# tviibh16m register map
Vendor: Infineon Technologies; Series: TVIIBH16M; File version: 1.0
CPU: CM7 r0p1, little endian, MPU, FPU, double-precision FPU, I-cache, D-cache, VTOR, ITCM, DTCM, 3 interrupt priority bits, 16 interrupts
Registers are 32-bit, read-write, reset 0x0 unless marked. A register's access mark holds for its fields unless they carry their own. Offsets are from the block's base; [hi:lo] are bit positions; {n}, {i} and the like mark numbered series; 'fields as' and 'values as' point back to an identical list.

## ETH0 (part 3 of 3) — Ethernet Interface
Base 0x40480000
Same registers: ETH1 0x40490000
0x11F8 TSU_PEER_RX_SEC ro — PTP Peer Event Frame Received Seconds Register (31 to 0 bits)
  [31:0] TIMER_PEER_SEC — PTP Peer Event Frame Received Seconds. The register is updated with the value that the 1588 timer seconds register held when the SFD of a PTP receive peer event crosses the MII interface. The actual update occurs when the GEM recognizes the frame as a PTP pdelay_req or pdelay_resp frame. An interrupt is issued when the register is updated.
0x11FC TSU_PEER_RX_NSEC ro — PTP Peer Event Frame Received Nanoseconds Register
  [29:0] TIMER_PEER_NSEC — PTP Peer Event Frame Received Nanoseconds. The register is updated with the value that the 1588 timer nanoseconds register held when the SFD of a PTP receive peer event crosses the MII interface. The actual update occurs when the GEM recognizes the frame as a PTP pdelay_req or pdelay_resp frame. An interrupt is issued when the register is updated.
0x1200 PCS_CONTROL ro — Not presents. Access to the register returns AHB error.
  [31:0] REMOVED_31_0 — Write ignore, read 0
0x1204 PCS_STATUS ro — Not presents. Access to the register returns AHB error.
  [31:0] REMOVED_31_0 — Write ignore, read 0
0x1210 PCS_AN_ADV ro — Not presents. Access to the register returns AHB error.
  [31:0] REMOVED_31_0 — Write ignore, read 0
0x1214 PCS_AN_LP_BASE ro — Not presents. Access to the register returns AHB error.
  [31:0] REMOVED_31_0 — Write ignore, read 0
0x1218 PCS_AN_EXP ro — Not presents. Access to the register returns AHB error.
  [31:0] REMOVED_31_0 — Write ignore, read 0
0x121C PCS_AN_NP_TX ro — Not presents. Access to the register returns AHB error.
  [31:0] REMOVED_31_0 — Write ignore, read 0
0x1220 PCS_AN_LP_NP ro — Not presents. Access to the register returns AHB error.
  [31:0] REMOVED_31_0 — Write ignore, read 0
0x123C PCS_AN_EXT_STATUS ro — Not presents. Access to the register returns AHB error.
  [31:0] REMOVED_31_0 — Write ignore, read 0
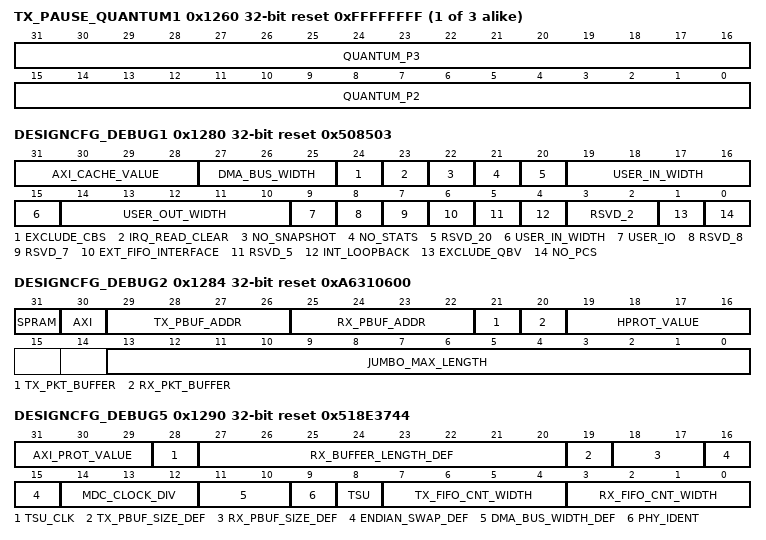
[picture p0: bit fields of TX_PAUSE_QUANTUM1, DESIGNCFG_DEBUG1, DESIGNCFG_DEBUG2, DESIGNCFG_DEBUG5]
{0x125C+4i} TX_PAUSE_QUANTUM{i} reset 0xFFFFFFFF (i=1..3) — Transmit Pause Quantum Register {i}
  [31:16] QUANTUM_P{2i+1} — Transmit pause quantum - written with the pause quantum value for pause frame transmission of priority {2i+1}.
  [15:0] QUANTUM_P{2i} — Transmit pause quantum - written with the pause quantum value for pause frame transmission of priority {2i}.
0x1270 RX_LPI ro — Received LPI transitions
  [15:0] COUNT_LPI read-clears — Count of RX LPI transitions. A count of the number of times there is a transition from receiving normal idle to receiving low power idle. Cleared on read.
0x1274 RX_LPI_TIME ro — Received LPI time
  [23:0] LPI_TIME read-clears — Time in LPI. This register increments once every 16 pclk cycles when the LPI indication bit 20 is set in the receive configuration register. Cleared on read.
0x1278 TX_LPI ro — Transmit LPI transitions
  [15:0] COUNT_LPI read-clears — Count of LPI transmissions. A count of the number of times the enable LPI transmission bit 20 goes from low to high in the transmit control register.
0x127C TX_LPI_TIME ro — Transmit LPI time
  [23:0] LPI_TIME read-clears — Time in LPI. This register increments once every 16 pclk cycles when the enable LPI transmission bit 20 is set in the transmit control register. Cleared on read.
0x1280 DESIGNCFG_DEBUG1 ro reset 0x508503 — The GEM_GXL(3PIP) has many parameterisation options to configure the IP during compilation stage. This is achieved using Verilog define compiler directives in an include file called mxeth_defs.v.
  [31:28] AXI_CACHE_VALUE — Takes the value of the `gem_axi_cache_value DEFINE
  [27:25] DMA_BUS_WIDTH — Takes the value of bits 7:5 of the `gem_dma_bus_width DEFINE. So if the define is set to decimal 64 this will return binary 010.
  [24] EXCLUDE_CBS — Takes the value of the `gem_exclude_cbs DEFINE
  [23] IRQ_READ_CLEAR — Takes the value of the `gem_irq_read_clear DEFINE
  [22] NO_SNAPSHOT — Takes the value of the `gem_no_snapshot DEFINE
  [21] NO_STATS — Takes the value of the `gem_no_stats DEFINE
  [20] RSVD_20
  [19:15] USER_IN_WIDTH — Takes the value of the `gem_user_in_width DEFINE `gem_user_io. If 'gem_user_io is not set, the value is 0x01
  [14:10] USER_OUT_WIDTH — Takes the value of the `gem_user_out_width DEFINE if `gem_user_io is set. If 'gem_user_io is not set, the value is 0x01
  [9] USER_IO — Takes the value of the `gem_user_io DEFINE
  [8] RSVD_8
  [7] RSVD_7
  [6] EXT_FIFO_INTERFACE — Takes the value of the `gem_ext_fifo_interface DEFINE
  [5] RSVD_5
  [4] INT_LOOPBACK — Takes the value of the `gem_int_loopback DEFINE
  [3:2] RSVD_2
  [1] EXCLUDE_QBV — Takes the value of the `gem_exclude_qbv DEFINE
  [0] NO_PCS — Takes the value of the `gem_no_pcs DEFINE
0x1284 DESIGNCFG_DEBUG2 ro reset 0xA6310600 — Design Configuration Register 2
  [31] SPRAM — Takes the value of the `gem_spram DEFINE
  [30] AXI — Takes the value of the `gem_axi DEFINE
  [29:26] TX_PBUF_ADDR — Takes the value of the `gem_tx_pbuf_addr DEFINE
  [25:22] RX_PBUF_ADDR — Takes the value of the `gem_rx_pbuf_addr DEFINE
  [21] TX_PKT_BUFFER — Takes the value of the `gem_tx_pkt_buffer DEFINE
  [20] RX_PKT_BUFFER — Takes the value of the `gem_rx_pkt_buffer DEFINE
  [19:16] HPROT_VALUE — Takes the value of the `gem_hprot_value DEFINE
  [13:0] JUMBO_MAX_LENGTH — Takes the value of the `gem_jumbo_max_length DEFINE
0x1288 DESIGNCFG_DEBUG3 ro reset 0x4000000 — Design Configuration Register 3
  [29:24] NUM_SPEC_ADD_FILTERS — Takes the value of the `num_spec_add_filters DEFINE
0x128C DESIGNCFG_DEBUG4 ro — Design Configuration Register 4
  [31:0] RSVD_31_0
0x1290 DESIGNCFG_DEBUG5 ro reset 0x518E3744 — Design Configuration Register 5
  [31:29] AXI_PROT_VALUE — Takes the value of the `gem_axi_prot_value DEFINE
  [28] TSU_CLK — Takes the value of the `gem_tsu_clk DEFINE
  [27:20] RX_BUFFER_LENGTH_DEF — Takes the value of the `gem_rx_buffer_length_def DEFINE
  [19] TX_PBUF_SIZE_DEF — Takes the value of the `gem_tx_pbuf_size_def DEFINE
  [18:17] RX_PBUF_SIZE_DEF — Takes the value of the `gem_rx_pbuf_size_def DEFINE
  [16:15] ENDIAN_SWAP_DEF — Takes the value of the `gem_endian_swap_def DEFINE
  [14:12] MDC_CLOCK_DIV — Takes the value of the `gem_mdc_clock_div DEFINE
  [11:10] DMA_BUS_WIDTH_DEF — Takes the value of the `gem_dma_bus_width_def DEFINE
  [9] PHY_IDENT — Takes the value of the `gem_phy_ident DEFINE
  [8] TSU — Takes the value of the `gem_tsu DEFINE
  [7:4] TX_FIFO_CNT_WIDTH — Takes the value of the `gem_tx_fifo_cnt_width DEFINE
  [3:0] RX_FIFO_CNT_WIDTH — Takes the value of the `gem_rx_fifo_cnt_width DEFINE
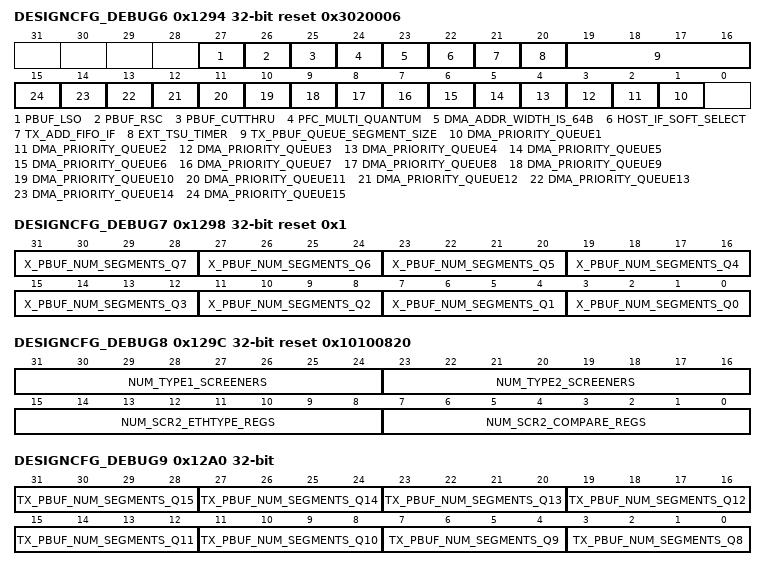
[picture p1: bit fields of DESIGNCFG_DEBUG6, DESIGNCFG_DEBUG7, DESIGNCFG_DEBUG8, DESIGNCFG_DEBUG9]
0x1294 DESIGNCFG_DEBUG6 ro reset 0x3020006 — Design Configuration Register 6
  [27] PBUF_LSO — Takes the value of the `gem_pbuf_lso DEFINE
  [26] PBUF_RSC — Takes the value of the `gem_pbuf_rsc DEFINE
  [25] PBUF_CUTTHRU — Takes the value of the `gem_pbuf_cutthru DEFINE
  [24] PFC_MULTI_QUANTUM — Takes the value of the `gem_pfc_multi_quantum DEFINE
  [23] DMA_ADDR_WIDTH_IS_64B — Takes the value of the `gem_dma_addr_width_is_64b DEFINE
  [22] HOST_IF_SOFT_SELECT — Takes the value of the `gem_host_if_soft_select DEFINE
  [21] TX_ADD_FIFO_IF — Takes the value of the `gem_tx_add_fifo_if DEFINE
  [20] EXT_TSU_TIMER — Takes the value of the `gem_ext_tsu_timer DEFINE
  [19:16] TX_PBUF_QUEUE_SEGMENT_SIZE — Takes the value of the `gem_tx_pbuf_queue_segment_size DEFINE
  [n] DMA_PRIORITY_QUEUE{n} (n=1..15) — Takes the value of the `dma_priority_queue{n} DEFINE
0x1298 DESIGNCFG_DEBUG7 ro reset 0x1 — Design Configuration Register 7
  [4n+3:4n] X_PBUF_NUM_SEGMENTS_Q{n} (n=0..7) — Takes the value of the `gem_tx_pbuf_num_segments_q{n} DEFINE
0x129C DESIGNCFG_DEBUG8 ro reset 0x10100820 — Design Configuration Register 8
  [31:24] NUM_TYPE1_SCREENERS — Takes the value of the `num_type1_screeners DEFINE
  [23:16] NUM_TYPE2_SCREENERS — Takes the value of the `num_type2_screeners DEFINE
  [15:8] NUM_SCR2_ETHTYPE_REGS — Takes the value of the `num_scr2_ethtype_regs DEFINE
  [7:0] NUM_SCR2_COMPARE_REGS — Takes the value of the `num_scr2_compare_regs DEFINE
0x12A0 DESIGNCFG_DEBUG9 ro — Design Configuration Register 9
  [4n-29:4n-32] TX_PBUF_NUM_SEGMENTS_Q{n} (n=8..15) — Takes the value of the `gem_tx_pbuf_num_segments_q{n} DEFINE
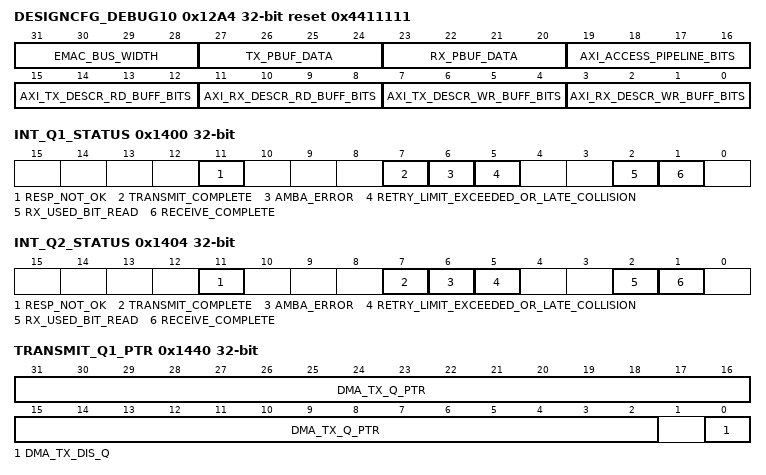
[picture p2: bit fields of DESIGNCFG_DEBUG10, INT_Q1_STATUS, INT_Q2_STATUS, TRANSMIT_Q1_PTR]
0x12A4 DESIGNCFG_DEBUG10 ro reset 0x4411111 — Design Configuration Register 10
  [31:28] EMAC_BUS_WIDTH — Takes the value of the `gem_emac_bus_width DEFINE. 1 - The MAC has a datawidth of 32bits. 2 - The MAC has a datawidth of 64bits. 4 - The MAC has a datawidth of 128bits
  [27:24] TX_PBUF_DATA — Takes the value of the `gem_tx_pbuf_data DEFINE. 1 - The TX DPRAM has a datawidth of 32bits. 2 - The TX DPRAM has a datawidth of 64bits. 4 - The TX DPRAM has a datawidth of 128bits
  [23:20] RX_PBUF_DATA — Takes the value of the `gem_rx_pbuf_data DEFINE. 1 - The RX DPRAM has a datawidth of 32bits. 2 - The RX DPRAM has a datawidth of 64bits. 4 - RX The DPRAM has a datawidth of 128bits
  [19:16] AXI_ACCESS_PIPELINE_BITS — Takes the value of the `gem_axi_access_pipeline_bits DEFINE
  [15:12] AXI_TX_DESCR_RD_BUFF_BITS — Takes the value of the `gem_axi_tx_descr_rd_buff_bits DEFINE
  [11:8] AXI_RX_DESCR_RD_BUFF_BITS — Takes the value of the `gem_axi_rx_descr_rd_buff_bits DEFINE
  [7:4] AXI_TX_DESCR_WR_BUFF_BITS — Takes the value of the `gem_axi_tx_descr_wr_buff_bits DEFINE
  [3:0] AXI_RX_DESCR_WR_BUFF_BITS — Takes the value of the `gem_axi_rx_descr_wr_buff_bits DEFINE
0x1300 SPEC_ADD5_BOTTOM ro — Specific address registers 5 ~ 36 doesn't present. Access to the register returns AHB error.
  [31:0] RSVD_31_0 — Write ignore, read 0
0x1304 SPEC_ADD5_TOP ro — Specific address registers 5 ~ 36 doesn't present. Access to the register returns AHB error.
  [31:0] RSVD_31_0 — Write ignore, read 0
0x13F8 SPEC_ADD36_BOTTOM ro — Not presents.
  [31:0] RSVD_31_0 — Write ignore, read 0
0x13FC SPEC_ADD36_TOP ro — Not presents.
  [31:0] RSVD_31_0 — Write ignore, read 0
0x1400 INT_Q1_STATUS ro — Priority queue Interrupt Status Register
  [11] RESP_NOT_OK — bresp not OK
  [7] TRANSMIT_COMPLETE
  [6] AMBA_ERROR — Transmit frame corruption due to AMBA (AXI/AHB) error set if an error occurs whilst midway through reading transmit frame from the external memory, including HRESP (AHB), RRESP and BRESP errors (AXI) and buffers exhausted mid frame
  [5] RETRY_LIMIT_EXCEEDED_OR_LATE_COLLISION
  [2] RX_USED_BIT_READ
  [1] RECEIVE_COMPLETE
0x1404 INT_Q2_STATUS ro — Priority queue Interrupt Status Register
  [11] RESP_NOT_OK — bresp not OK
  [7] TRANSMIT_COMPLETE
  [6] AMBA_ERROR — Transmit frame corruption due to AMBA (AXI/AHB) error set if an error occurs whilst midway through reading transmit frame from the external memory, including HRESP(AHB), RRESP and BRESP errors (AXI) and buffers exhausted mid frame
  [5] RETRY_LIMIT_EXCEEDED_OR_LATE_COLLISION
  [2] RX_USED_BIT_READ
  [1] RECEIVE_COMPLETE
0x1408 INT_Q3_STATUS ro — int_q3_status to int_q15_status doesn't present. Access to the register returns AHB error.
  [31:0] REMOVED_31_0 — Write ignore, read 0
0x1438 INT_Q15_STATUS ro — Not presents.
  [31:0] REMOVED_31_0 — Write ignore, read 0
0x1440 TRANSMIT_Q1_PTR — This register holds the start address of the transmit buffer queue (transmit buffers descriptor list). The transmit buffer queue base address register must be initialized before transmit is started through bit 9 of the network control register. Once transmission has started, any write to the transmit buffer queue base address register is illegal and therefore ignored. Note that due to clock boundary synchronization, it takes a maximum of four pclk cycles from the writing of the transmit start bit before the transmitter is active. Writing to the transmit buffer queue base address register during this time may produce unpredictable results. Reading this register returns the location of the descriptor currently being accessed. Because the DMA can store data for multiple frames at once, this may not necessarily be pointing to the current frame being transmitted. In terms of AMBA AXI operation, the transmit descriptors are written to memory using a single 32bit AHB access. When the datapath is configured as 64bit , the transmit descriptors should be aligned at 64-bit boundaries and each pair of 32-bit descriptors is read from memory using a single AXI access.
  [31:2] DMA_TX_Q_PTR — This register holds the start address of the transmit buffer queue (transmit buffers descriptor list). The transmit buffer queue base address register must be initialized before transmit is started through bit 9 of the network control register. Once transmission has started, any write to the transmit buffer queue base address register is illegal and therefore ignored. Note that due to clock boundary synchronization, it takes a maximum of four pclk cycles from the writing of the transmit start bit before the transmitter is active. Writing to the transmit buffer queue base address register during this time may produce unpredictable results. Reading this register returns the location of the descriptor currently being accessed. Because the DMA can store data for multiple frames at once, this may not necessarily be pointing to the current frame being transmitted. In terms of AMBA AHB/AXI operation, the transmit descriptors are written to memory using a single 32bit AHB access. When the datapath is configured as 64bit or 128bit, the transmit descriptors should be aligned at 64-bit boundaries and each pair of 32-bit descriptors is read from memory using a single AHB/AXI access. For 32bit datapaths, the descriptors should be aligned at 32-bit boundaries and the descriptors are read from memory using two individual 32-bit non sequential accesses.
  [0] DMA_TX_DIS_Q — Disable queue if set to 1. This can be used to reduce the number of active queues and should only be changed while transmit is not enabled.
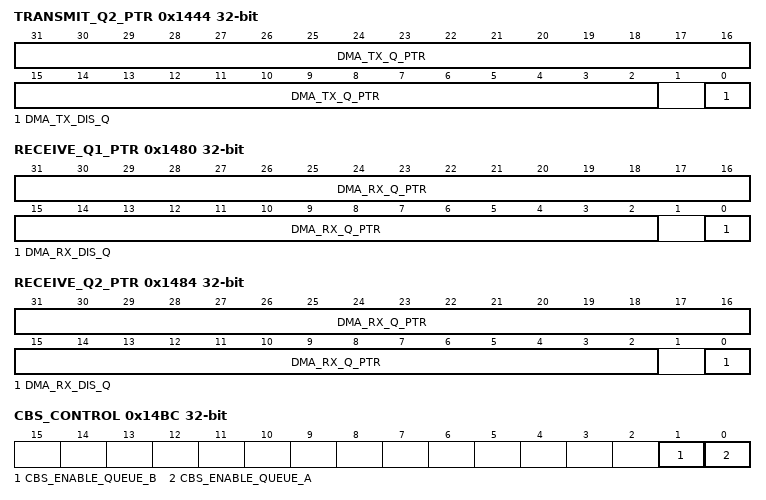
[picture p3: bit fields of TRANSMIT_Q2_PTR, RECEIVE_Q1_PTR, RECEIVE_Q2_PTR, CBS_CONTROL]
0x1444 TRANSMIT_Q2_PTR — This register holds the start address of the transmit buffer queue (transmit buffers descriptor list). The transmit buffer queue base address register must be initialized before transmit is started through bit 9 of the network control register. Once transmission has started, any write to the transmit buffer queue base address register is illegal and therefore ignored. Note that due to clock boundary synchronization, it takes a maximum of four pclk cycles from the writing of the transmit start bit before the transmitter is active. Writing to the transmit buffer queue base address register during this time may produce unpredictable results. Reading this register returns the location of the descriptor currently being accessed. Because the DMA can store data for multiple frames at once, this may not necessarily be pointing to the current frame being transmitted. In terms of AMBA AXI operation, the transmit descriptors are written to memory using a single 32bit AHB access. When the datapath is configured as 64bit , the transmit descriptors should be aligned at 64-bit boundaries and each pair of 32-bit descriptors is read from memory using a single AXI access.
  [31:2] DMA_TX_Q_PTR — This register holds the start address of the transmit buffer queue (transmit buffers descriptor list). The transmit buffer queue base address register must be initialized before transmit is started through bit 9 of the network control register. Once transmission has started, any write to the transmit buffer queue base address register is illegal and therefore ignored. Note that due to clock boundary synchronization, it takes a maximum of four pclk cycles from the writing of the transmit start bit before the transmitter is active. Writing to the transmit buffer queue base address register during this time may produce unpredictable results. Reading this register returns the location of the descriptor currently being accessed. Because the DMA can store data for multiple frames at once, this may not necessarily be pointing to the current frame being transmitted. In terms of AMBA AHB/AXI operation, the transmit descriptors are written to memory using a single 32bit AHB access. When the datapath is configured as 64bit or 128bit, the transmit descriptors should be aligned at 64-bit boundaries and each pair of 32-bit descriptors is read from memory using a single AHB/AXI access. For 32bit datapaths, the descriptors should be aligned at 32-bit boundaries and the descriptors are read from memory using two individual 32-bit non sequential accesses
  [0] DMA_TX_DIS_Q — Disable queue if set to 1. This can be used to reduce the number of active queues and should only be changed while transmit is not enabled.
0x1448 TRANSMIT_Q3_PTR ro — transmit_q3_ptr to transmit_q15_ptr doesn't present. Access to the register returns AHB error.
  [31:0] REMOVED_31_0 — Disable queue if set to 1. This can be used to reduce the number of active queues and should only be changed while transmit is not enabled.
0x1478 TRANSMIT_Q15_PTR ro — Not presents.
  [31:0] REMOVED_31_0 — Write ignore, read 0
0x1480 RECEIVE_Q1_PTR — This register holds the start address of the transmit buffer queue (transmit buffers descriptor list). The transmit buffer queue base address register must be initialized before transmit is started through bit 9 of the network control register. Once transmission has started, any write to the transmit buffer queue base address register is illegal and therefore ignored. Note that due to clock boundary synchronization, it takes a maximum of four pclk cycles from the writing of the transmit start bit before the transmitter is active. Writing to the transmit buffer queue base address register during this time may produce unpredictable results. Reading this register returns the location of the descriptor currently being accessed. Because the DMA can store data for multiple frames at once, this may not necessarily be pointing to the current frame being transmitted. In terms of AMBA AXI operation, the transmit descriptors are written to memory using a single 32bit AHB access. When the datapath is configured as 64bit , the transmit descriptors should be aligned at 64-bit boundaries and each pair of 32-bit descriptors is read from memory using a single AXI access.
  [31:2] DMA_RX_Q_PTR — Receive buffer queue base address - written with the address of the start of the receive queue.
  [0] DMA_RX_DIS_Q — Disable queue if set to 1. This can be used to reduce the number of active queues and should only be changed while receive is not enabled.
0x1484 RECEIVE_Q2_PTR — This register holds the start address of the transmit buffer queue (transmit buffers descriptor list). The transmit buffer queue base address register must be initialized before transmit is started through bit 9 of the network control register. Once transmission has started, any write to the transmit buffer queue base address register is illegal and therefore ignored. Note that due to clock boundary synchronization, it takes a maximum of four pclk cycles from the writing of the transmit start bit before the transmitter is active. Writing to the transmit buffer queue base address register during this time may produce unpredictable results. Reading this register returns the location of the descriptor currently being accessed. Because the DMA can store data for multiple frames at once, this may not necessarily be pointing to the current frame being transmitted. In terms of AMBA AXI operation, the transmit descriptors are written to memory using a single 32bit AHB access. When the datapath is configured as 64bit , the transmit descriptors should be aligned at 64-bit boundaries and each pair of 32-bit descriptors is read from memory using a single AXI access.
  fields as RECEIVE_Q1_PTR
0x1488 RECEIVE_Q3_PTR ro — Not presents. Start address register doesn't present for queue3 ~ queue7.
  [31:0] REMOVED_31_0 — Write ignore, read 0
0x1498 RECEIVE_Q7_PTR ro — Not presents.
  [31:0] REMOVED_31_0 — Write ignore, read 0
0x14A0 DMA_RXBUF_SIZE_Q1 reset 0x18 — Receive Buffer queue 1 Size
  [7:0] DMA_RX_Q_BUF_SIZE — DMA receive buffer size in system memory. The value defined by these bits determines the size of buffer to use in main system memory when writing received data. The value is defined in multiples of 64 bytes. 0x01 corresponds to buffers of 64 bytes. 0x02 corresponds to 128 bytes etc. For example: 0x02: 128 byte 0x18: 1536 byte (1*max length frame/buffer) 0xA0: 10240 byte (1*10K jumbo frame/buffer) Note that this value should never be written as zero. Note. The reset value of this field is equal to the gem_rx_buffer_length_def define, which is user configurable.
0x14A4 DMA_RXBUF_SIZE_Q2 reset 0x18 — Receive Buffer queue 2 Size
  fields as DMA_RXBUF_SIZE_Q1
0x14A8 DMA_RXBUF_SIZE_Q3 ro — dma_rxbuf_size_q3 to dma_rxbuf_size_q7 doesn't present.
  [31:0] REMOVED_31_0 — DMA receive buffer size in system memory. The value defined by these bits determines the size of buffer to use in main system memory when writing received data. The value is defined in multiples of 64 bytes. 0x01 corresponds to buffers of 64 bytes. 0x02 corresponds to 128 bytes etc. For example: 0x02: 128 byte 0x18: 1536 byte (1*max length frame/buffer) 0xA0: 10240 byte (1*10K jumbo frame/buffer) Note that this value should never be written as zero. Note. The reset value of this field is equal to the gem_rx_buffer_length_def define, which is user configurable.
0x14B8 DMA_RXBUF_SIZE_Q7 ro — Not presents.
  [31:0] REMOVED_31_0 — Write ignore, read 0
0x14BC CBS_CONTROL — The IdleSlope value is defined as the rate of change of credit when a packet is waiting to be sent. This must not exceed the portTransmitRate which is dependent on the speed of operation, eg, portTranmsitRate. 1Gb/s = 32'h07735940 (125 Mbytes/s), 100Mb/sec = 32'h017D7840 (25 Mnibbles/s), 10Mb/sec = 32'h002625A0 (2.5 Mnibbles/s). If 50 percent of bandwidth was to be allocated to a particular queue in 1Gb/sec mode then the IdleSlope value for that queue would be calculated as 32'h07735940/2. Note that Credit-Based Shaping should be disabled prior to updating the IdleSlope values. As another example, for a 1722 audio packet with a payload of 6 samples per channel, the packet size would be 7 (preamble) + 1 (SFD) + 50 (packet header) + 6x4x2(payload) + 4 (CRC) = 110 bytes. For a rate of 8000 packets per second, the desired rate would 110 x 8000 bytes per second, so the programmed idleSlope value would be 880000 for a 1Gb/s connection, or 1760000 for a 100Mb/s or 10Mbs connection. See Figure 6.3 in the IEEE 1722 standard. In practice, the actual transmission rate will be vary slightly from that calculated. In this case, the idleSlope value should be recalibrated based on the variance between the measured and expected rate, and in this case very accurate transmission rates can be achieved.
  [1] CBS_ENABLE_QUEUE_B — Enable Credit-Based shaping on the 2nd highest priority queue (queue B). Write 1 to enable
  [0] CBS_ENABLE_QUEUE_A — Enable Credit-Based Shaping on the highest priority queue (queue A). Write 1 to enable
0x14C0 CBS_IDLESLOPE_Q_A — queue A is the highest priority queue. This would be queue 8 in an 8 queue configuration.
  [31:0] IDLESLOPE_A — IdleSlope value for queue A in bytes/sec for gigabit operation and nibbles/sec for 10/100 operation
0x14C4 CBS_IDLESLOPE_Q_B — queue B is the 2nd highest priority queue. This would be queue 7 in an 8 queue configuration.
  [31:0] IDLESLOPE_B — IdleSlope value for queue B in bytes/sec for gigabit operation and nibbles/sec for 10/100 operation
0x14C8 UPPER_TX_Q_BASE_ADDR — Upper 32 bits of transmit buffer descriptor queue base address.
  [31:0] UPPER_TX_Q_BASE_ADDR — Upper 32 bits of transmit buffer descriptor queue base address. Used when 64 bit addressing is enabled. (In releases earlier to 1p06f2 this register also affected the receive descriptor queue.)
0x14CC TX_BD_CONTROL
  [5:4] TX_BD_TS_MODE — TX Descriptor Timestamp Insertion mode, 00: TS insertion disable, 01: TS inserted for PTP Event Frames only, 10: TS inserted for All PTP Frames only, 11: TS insertion for All Frames
0x14D0 RX_BD_CONTROL
  [5:4] RX_BD_TS_MODE — RX Descriptor Timestamp Insertion mode, 00: TS insertion disable, 01: TS inserted for PTP Event Frames only, 10: TS inserted for All PTP Frames only, 11: TS insertion for All Frames
0x14D4 UPPER_RX_Q_BASE_ADDR — Upper 32 bits of receive buffer descriptor queue base address.
  [31:0] UPPER_RX_Q_BASE_ADDR — Upper 32 bits of receive buffer descriptor queue base address. Used when 64 bit addressing is enabled.
0x14E0 HIDDEN_REG0 reset 0x2625A0 — Hidden registers defined in edma_defs.v '`define gem_cbs_port_tx_rate_10m 12'h4e0 // 10M Port TX Rate *** HIDDEN Register ***'. Default value of cbs related hidden registers (0x14E0~0x14E8) are depicted in cbs_control register.
  [31:0] HIDDEN0_FIELD — default value is defined per description of register cbs_control.
0x14E4 HIDDEN_REG1 reset 0x17D7840 — Hidden registers defined in edma_defs.v '`define gem_cbs_port_tx_rate_100m 12'h4e4 // 100M Port TX Rate *** HIDDEN Register ***'
  [31:0] HIDDEN1_FIELD — default value is defined per description of register cbs_control.
0x14E8 HIDDEN_REG2 reset 0x7735940 — Hidden registers defined in edma_defs.v '`define gem_cbs_port_tx_rate_1g 12'h4e8 // 1G Port TX Rate *** HIDDEN Register ***'
  [31:0] HIDDEN2_FIELD — default value is defined per description of register cbs_control.
0x14EC HIDDEN_REG3 reset 0x7 — Hidden registers defined in edma_defs.v '`define gem_wd_counter 12'h4ec // *** HIDDEN Register ***'.
  [3:0] HIDDEN3_FIELD — default value is defined per description of register cbs_control.
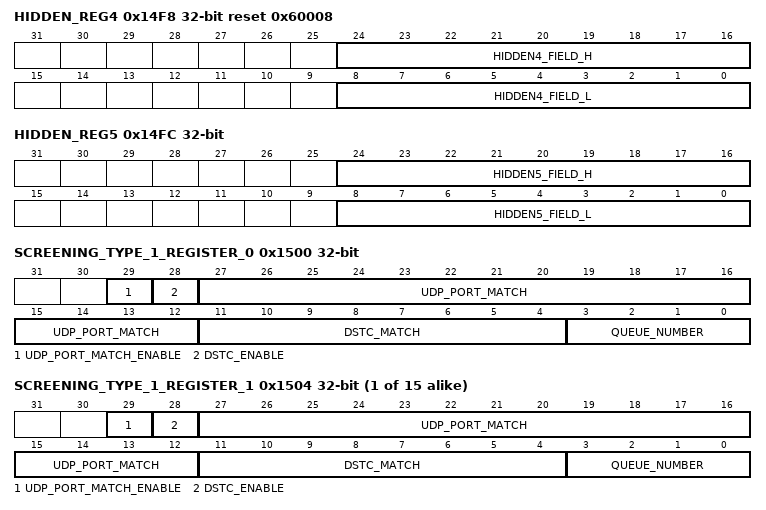
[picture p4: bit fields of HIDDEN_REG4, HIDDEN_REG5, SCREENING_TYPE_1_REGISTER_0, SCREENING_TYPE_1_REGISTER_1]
0x14F8 HIDDEN_REG4 reset 0x60008 — Hidden registers defined in edma_defs.v '`define gem_axi_tx_full_threshold0 12'h4f8 // AXI full threshold setting *** HIDDEN Register ***'. Note. When using AXI mode with a single port ram ( gem_spram == 1) mode and a 32b dma bus width ( gem_dma_bus_width == 32 or bits 22 to 21 of the network_config register are set to 0) the AXI hidden registers (0x14F8 and 0x14FC) need to be updated (these registers are used for fine tuning AXI dma bursts and normally should not be touched).
  [24:16] HIDDEN4_FIELD_H — The valid bits is defined by `gem_tx_pbuf_addr.
  [8:0] HIDDEN4_FIELD_L — The valid bits is defined by `gem_tx_pbuf_addr.
0x14FC HIDDEN_REG5 — Hidden registers defined in edma_defs.v '`define gem_axi_tx_full_threshold1 12'h4fc // AXI full threshold setting *** HIDDEN Register ***'.
  [24:16] HIDDEN5_FIELD_H — The valid bits is defined by `gem_tx_pbuf_addr.
  [8:0] HIDDEN5_FIELD_L — The valid bits is defined by `gem_tx_pbuf_addr.
0x1500 SCREENING_TYPE_1_REGISTER_0 — Screening type 1 registers are used to allocate up to 16 priority queues to received frames based on certain IP or UDP fields of incoming frames. Firstly, when DS/TC match enable is set (bit 28), the DS (Differentiated Services) field of the received IPv4 header or TCfield (traffic class) of IPv6 headers are matched against bits 11 to 4. Secondly, when UDP port match enable is set (bit 29), the UDP Destination Port of the received UDP frame is matched against bits 27 to 12. Both UDP and DS/TC matching can be enabled simultaneously or individually. If a match is successful, then the queue value programmed in bits 2 to 0 is allocated to the frame. The required number of Type 1 screening registers is configured in the gem defines file. Up to 16 type 1 screening registers have been allocated APB address space between 0x500 and 0x53C.
  [29] UDP_PORT_MATCH_ENABLE
  [28] DSTC_ENABLE
  [27:12] UDP_PORT_MATCH
  [11:4] DSTC_MATCH
  [3:0] QUEUE_NUMBER — Queue Number (0 to 15)
{0x1500+4i} SCREENING_TYPE_1_REGISTER_{i} (i=1..15) — screening type 1 register {i}, same as screening_type_1_register_0
  fields as SCREENING_TYPE_1_REGISTER_0
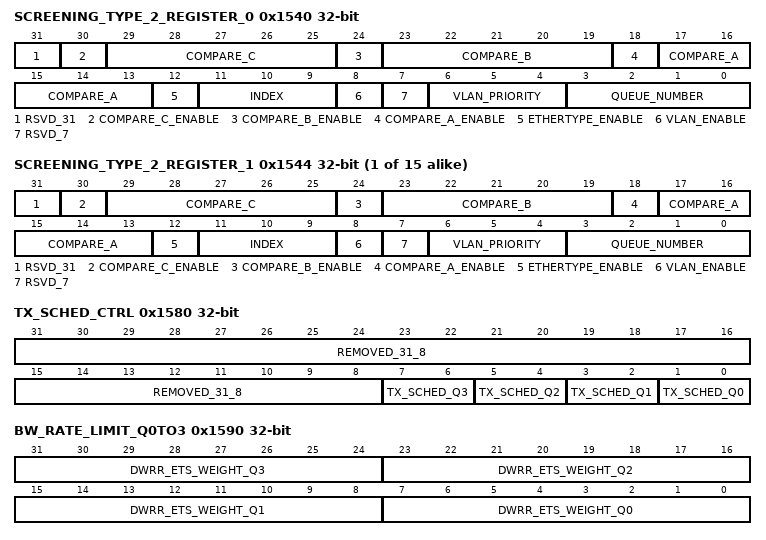
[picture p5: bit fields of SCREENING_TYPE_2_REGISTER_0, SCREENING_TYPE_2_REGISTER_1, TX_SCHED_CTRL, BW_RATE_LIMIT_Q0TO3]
0x1540 SCREENING_TYPE_2_REGISTER_0 — Screener Type 2 match registers operate independently of screener type 1 registers and offer additional match capabilities, extending the capabilities into vendor specific protocols.
  [31] RSVD_31 ro
  [30] COMPARE_C_ENABLE
  [29:25] COMPARE_C — 'Compare C - Index to screener type 2 Compare register'
  [24] COMPARE_B_ENABLE
  [23:19] COMPARE_B — 'Compare B - Index to screener type 2 Compare register'
  [18] COMPARE_A_ENABLE
  [17:13] COMPARE_A — 'Compare A - Index to screener type 2 Compare register '
  [12] ETHERTYPE_ENABLE
  [11:9] INDEX — 'Index to screener type 2 EtherType register'
  [8] VLAN_ENABLE
  [7] RSVD_7
  [6:4] VLAN_PRIORITY
  [3:0] QUEUE_NUMBER — 'Queue Number (0 to 15)'
{0x1540+4i} SCREENING_TYPE_2_REGISTER_{i} (i=1..15) — screening type 2 register {i}, same as screening_type_2_register_0
  fields as SCREENING_TYPE_2_REGISTER_0
0x1580 TX_SCHED_CTRL — This register controls the transmit scheduling algorithm the user can select for each active transmit queue. By default all queues are initialized to fixed priority, with the top indexed queue having overall priority
  [31:8] REMOVED_31_8 ro — Write ignore, read 0
  [7:6] TX_SCHED_Q3 ro — Write ignore, read 0
  [5:4] TX_SCHED_Q2 — 'Queue 2 selection. 00 : Fixed Priority 01 : CBS Enabled only valid for top two enabled queues and if CBS capability selected. 10 : DWRR Enabled 11 : ETS Enabled
  [3:2] TX_SCHED_Q1 — 'Queue 1 selection. 00 : Fixed Priority 01 : CBS Enabled only valid for top two enabled queues and if CBS capability selected. 10 : DWRR Enabled 11 : ETS Enabled'
  [1:0] TX_SCHED_Q0 — 'Queue 0 selection. 00 : Fixed Priority 01 : CBS Enabled only valid for top two enabled queues and if CBS capability selected. 10 : DWRR Enabled 11 : ETS Enabled'
0x1590 BW_RATE_LIMIT_Q0TO3 — This register holds the DWRR weighting value or the ETS bandwidth percentage value used by the transmit scheduler for queues 0 to 3.
  [31:24] DWRR_ETS_WEIGHT_Q3 ro — Write ignore, read 0
  [23:16] DWRR_ETS_WEIGHT_Q2 — 'DWRR Weighting / ETS Bandwidth Allocation for queue 2'
  [15:8] DWRR_ETS_WEIGHT_Q1 — 'DWRR Weighting / ETS Bandwidth Allocation for queue 1'
  [7:0] DWRR_ETS_WEIGHT_Q0 — 'DWRR Weighting / ETS Bandwidth Allocation for queue 0'
0x1594 BW_RATE_LIMIT_Q4TO7 — Not presents. MXETH has only 3 queues. Access to the register returns AHB error.
  [31:0] REMOVED_31_0 — 'DWRR Weighting / ETS Bandwidth Allocation for queue 0'
0x1598 BW_RATE_LIMIT_Q8TO11 ro — Not presents. MXETH has only 3 queues. Access to the register returns AHB error.
  [31:0] REMOVED_31_0 — Write ignore, read 0
0x159C BW_RATE_LIMIT_Q12TO15 ro — Not presents. MXETH has only 3 queues. Access to the register returns AHB error.
  [31:0] REMOVED_31_0 — Write ignore, read 0
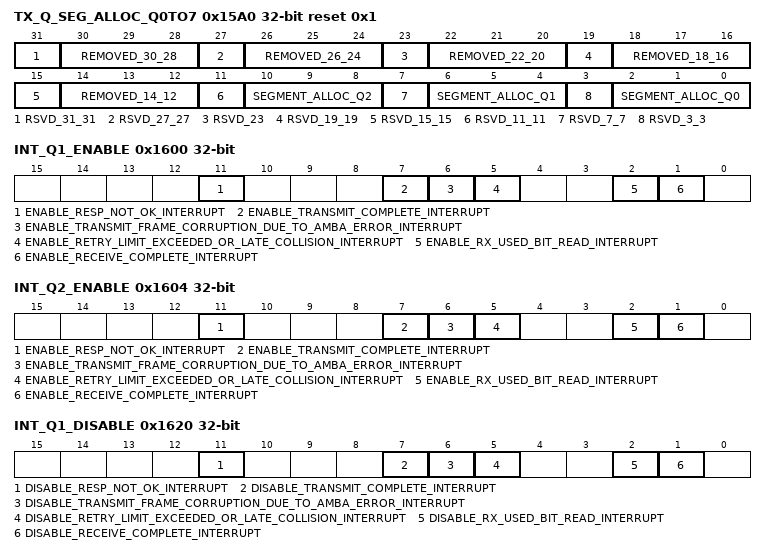
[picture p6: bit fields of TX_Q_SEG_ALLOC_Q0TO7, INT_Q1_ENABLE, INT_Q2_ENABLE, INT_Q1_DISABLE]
0x15A0 TX_Q_SEG_ALLOC_Q0TO7 reset 0x1 — This register allows the user to distribute the Transmit SRAM used by the DMA across the priority queues, for queues 0 to 7. The SRAM itself is split into a number of evenly sized segments (this is defined in the verilog configuration defs file - for the configuration used to generate this register description, the total number of segments was set to '16'). Those segments can then be freely distributed across the active queues, in powers of 2. I.e. a value of 0 would mean 1 segment has been allocated to the queue. A value of 1 would mean 2 segments, a value of 2 means 4 segments and so on. The reset values of these registers are defined in the configuration defs file.
  [31] RSVD_31_31 ro — Write ignore, read 0
  [30:28] REMOVED_30_28 ro — Write ignore, read 0
  [27] RSVD_27_27 ro — Write ignore, read 0
  [26:24] REMOVED_26_24 ro — Write ignore, read 0
  [23] RSVD_23 ro — Write ignore, read 0
  [22:20] REMOVED_22_20 ro — Write ignore, read 0
  [19] RSVD_19_19 ro — Write ignore, read 0
  [18:16] REMOVED_18_16 ro — Write ignore, read 0
  [15] RSVD_15_15 ro — Write ignore, read 0
  [14:12] REMOVED_14_12 ro — Write ignore, read 0
  [11] RSVD_11_11 ro — Write ignore, read 0
  [10:8] SEGMENT_ALLOC_Q2 — Number of segments allocated to q2. This should be entered as a log 2, for example entering a value of 2 would grant 4 segments. A maximum of 32 segments can be granted
  [7] RSVD_7_7 ro
  [6:4] SEGMENT_ALLOC_Q1 — Number of segments allocated to q1. This should be entered as a log 2, for example entering a value of 2 would grant 4 segments. A maximum of 32 segments can be granted
  [3] RSVD_3_3 ro
  [2:0] SEGMENT_ALLOC_Q0 — Number of segments allocated to q0. This should be entered as a log 2, for example entering a value of 2 would grant 4 segments. A maximum of 32 segments can be granted. The default value is determined by `gem_tx_pbuf_num_segments_q0
0x15A4 TX_Q_SEG_ALLOC_Q8TO15 ro — Not presents. Access to the register returns AHB error.
  [31:0] REMOVED_31_0 — Write ignore, read 0
0x15C0 RECEIVE_Q8_PTR ro — receive_q8_ptr to receive_q15_ptr doesn't present. Access to the register returns AHB error.
  [31:0] REMOVED_31_0 — Write ignore, read 0
0x15DC RECEIVE_Q15_PTR ro — Not presents.
  [31:0] REMOVED_31_0 — Write ignore, read 0
0x15E0 DMA_RXBUF_SIZE_Q8 ro — dma_rxbuf_size_q8 to dma_rxbuf_size_q15 doesn't present. Access to the register returns AHB error.
  [31:0] REMOVED_31_0 — Write ignore, read 0
0x15FC DMA_RXBUF_SIZE_Q15 ro — Not presents.
  [31:0] REMOVED_31_0 — Write ignore, read 0
0x1600 INT_Q1_ENABLE wo — At reset all interrupts are disabled. Writing a one to the relevant bit location enables the required interrupt. This register is write only and when read will return zero.
  [11] ENABLE_RESP_NOT_OK_INTERRUPT — Enable bresp not OK interrupt
  [7] ENABLE_TRANSMIT_COMPLETE_INTERRUPT
  [6] ENABLE_TRANSMIT_FRAME_CORRUPTION_DUE_TO_AMBA_ERROR_INTERRUPT — Enable Transmit frame corruption due to AMBA (AXI/AHB) error interrupt
  [5] ENABLE_RETRY_LIMIT_EXCEEDED_OR_LATE_COLLISION_INTERRUPT
  [2] ENABLE_RX_USED_BIT_READ_INTERRUPT
  [1] ENABLE_RECEIVE_COMPLETE_INTERRUPT
0x1604 INT_Q2_ENABLE wo — At reset all interrupts are disabled. Writing a one to the relevant bit location enables the required interrupt. This register is write only and when read will return zero.
  fields as INT_Q1_ENABLE
0x1608 INT_Q3_ENABLE ro — int_q3_enable to int_q7_enable doesn't present. Access to the register returns AHB error.
  [31:0] REMOVED_31_0 — Write ignore, read 0
0x1618 INT_Q7_ENABLE ro — Not presents.
  [31:0] REMOVED_31_0 — Write ignore, read 0
0x1620 INT_Q1_DISABLE wo — Writing a 1 to the relevant bit location disables that particular interrupt. This register is write only and when read will return zero.
  [11] DISABLE_RESP_NOT_OK_INTERRUPT — Disable bresp not OK interrupt
  [7] DISABLE_TRANSMIT_COMPLETE_INTERRUPT
  [6] DISABLE_TRANSMIT_FRAME_CORRUPTION_DUE_TO_AMBA_ERROR_INTERRUPT — Disable Transmit frame corruption due to AMBA (AXI/AHB) error interrupt
  [5] DISABLE_RETRY_LIMIT_EXCEEDED_OR_LATE_COLLISION_INTERRUPT
  [2] DISABLE_RX_USED_BIT_READ_INTERRUPT
  [1] DISABLE_RECEIVE_COMPLETE_INTERRUPT
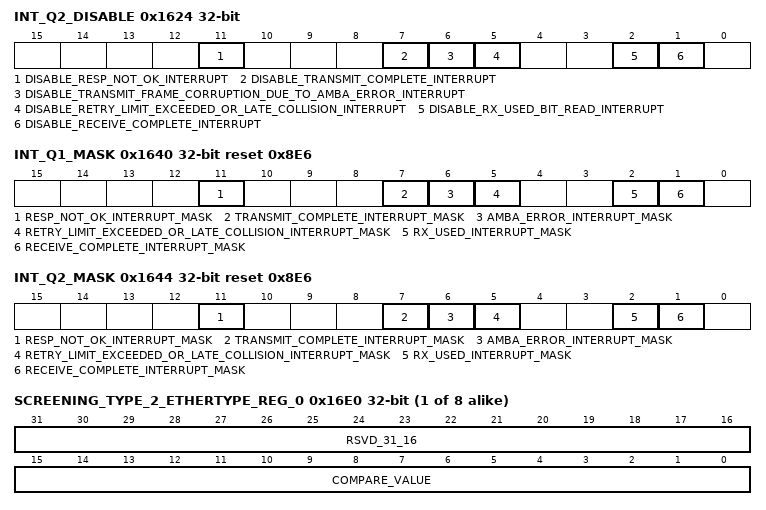
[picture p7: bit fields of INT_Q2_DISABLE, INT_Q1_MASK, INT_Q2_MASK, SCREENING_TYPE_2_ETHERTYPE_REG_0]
0x1624 INT_Q2_DISABLE wo — Writing a 1 to the relevant bit location disables that particular interrupt. This register is write only and when read will return zero.
  fields as INT_Q1_DISABLE
0x1628 INT_Q3_DISABLE ro — int_q3_disable to int_q7_disable doesn't present. Access to the register returns AHB error.
  [31:0] REMOVED_31_0 — Write ignore, read 0
0x1638 INT_Q7_DISABLE ro — Not presents.
  [31:0] REMOVED_31_0 — Write ignore, read 0
0x1640 INT_Q1_MASK ro reset 0x8E6 — The interrupt mask register is a read only register indicating which interrupts are masked. All bits are set at reset and can be reset individually by writing to the interrupt enable register or set individually by writing to the interrupt disable register. Having separate address locations for enable and disable saves the need for performing a read modify write when updating the interrupt mask register. For test purposes there is a write-only function to this register that allows the bits in the interrupt status register to be set or cleared, regardless of the state of the mask register.
  [11] RESP_NOT_OK_INTERRUPT_MASK — bresp not OK interrupt mask. 0: Interrupt is enabled. 1: Interrupt is disabled. A write to this register directly affects the state of the corresponding bit in the interrupt status register, causing an interrupt to be generated if a 1 is written.
  [7] TRANSMIT_COMPLETE_INTERRUPT_MASK — transmit complete interrupt mask. 0: Interrupt is enabled. 1: Interrupt is disabled. A write to this register directly affects the state of the corresponding bit in the interrupt status register, causing an interrupt to be generated if a 1 is written.
  [6] AMBA_ERROR_INTERRUPT_MASK — A read of this register returns the value of the AMBA (AXI/AHB) error interrupt mask. 0: Interrupt is enabled. 1: Interrupt is disabled. A write to this register directly affects the state of the corresponding bit in the interrupt status register, causing an interrupt to be generated if a 1 is written.
  [5] RETRY_LIMIT_EXCEEDED_OR_LATE_COLLISION_INTERRUPT_MASK — retry limit exceeded or late collision interrupt mask. 0: Interrupt is enabled. 1: Interrupt is disabled. A write to this register directly affects the state of the corresponding bit in the interrupt status register, causing an interrupt to be generated if a 1 is written.
  [2] RX_USED_INTERRUPT_MASK — A read of this register returns the value of the RX Used interrupt mask. 0: Interrupt is enabled. 1: Interrupt is disabled. A write to this register directly affects the state of the corresponding bit in the interrupt status register, causing an interrupt to be generated if a 1 is written.
  [1] RECEIVE_COMPLETE_INTERRUPT_MASK — receive complete interrupt mask. 0: Interrupt is enabled. 1: Interrupt is disabled. A write to this register directly affects the state of the corresponding bit in the interrupt status register, causing an interrupt to be generated if a 1 is written.
0x1644 INT_Q2_MASK ro reset 0x8E6 — The interrupt mask register is a read only register indicating which interrupts are masked. All bits are set at reset and can be reset individually by writing to the interrupt enable register or set individually by writing to the interrupt disable register. Having separate address locations for enable and disable saves the need for performing a read modify write when updating the interrupt mask register. For test purposes there is a write-only function to this register that allows the bits in the interrupt status register to be set or cleared, regardless of the state of the mask register.
  fields as INT_Q1_MASK
0x1648 INT_Q3_MASK ro — int_q3_mask to int_q7_mask doesn't present. Access to the register returns AHB error.
  [31:0] REMOVED_31_0 — Write ignore, read 0
0x1658 INT_Q7_MASK ro — Not presents.
  [31:0] REMOVED_31_0 — Write ignore, read 0
0x1660 INT_Q8_ENABLE ro — int_q8_enable to int_q15_enable doesn't present. Access to the register returns AHB error.
  [31:0] REMOVED_31_0 — Write ignore, read 0
0x167C INT_Q15_ENABLE ro — Not presents.
  [31:0] REMOVED_31_0 — Write ignore, read 0
0x1680 INT_Q8_DISABLE ro — int_q8_disable to int_q15_disable doesn't present. Access to the register returns AHB error.
  [31:0] REMOVED_31_0 — Write ignore, read 0
0x169C INT_Q15_DISABLE ro — Not presents.
  [31:0] REMOVED_31_0 — Write ignore, read 0
0x16A0 INT_Q8_MASK ro — int_q8_mask to int_q15_mask doesn't present. Access to the register returns AHB error.
  [31:0] REMOVED_31_0 — Write ignore, read 0
0x16BC INT_Q15_MASK ro — Not presents.
  [31:0] REMOVED_31_0 — Write ignore, read 0
{0x16E0+4i} SCREENING_TYPE_2_ETHERTYPE_REG_{i} (i=0..7) — Ethertype Register
  [31:16] RSVD_31_16 ro
  [15:0] COMPARE_VALUE — 'EtherType compare value'
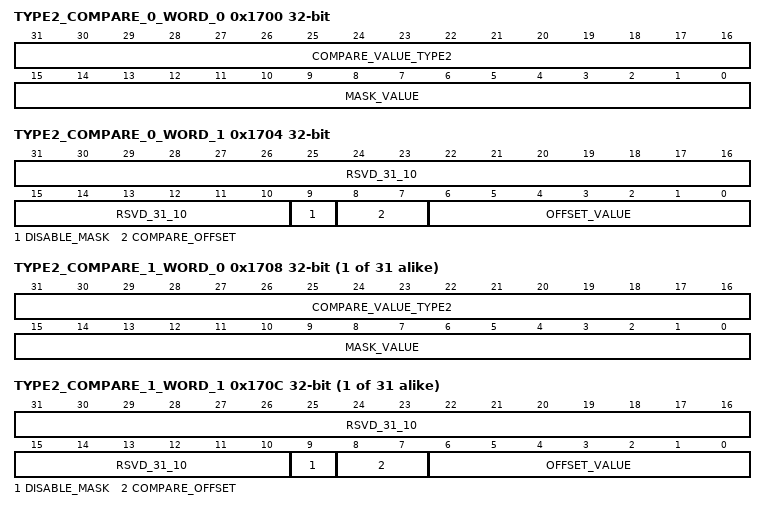
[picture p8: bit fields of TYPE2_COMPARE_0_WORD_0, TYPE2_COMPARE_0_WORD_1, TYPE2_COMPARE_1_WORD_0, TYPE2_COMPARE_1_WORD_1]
0x1700 TYPE2_COMPARE_0_WORD_0 — 'Compare A, B and C fields of the screener type 2 match register are pointers to a pool of up to 32 compare registers. If enabled the compare is true if the data at the OFFSET into the frame, ANDed with the MASK Value if the mask is enabled, is equal to the COMPARE Value. Either a 16 bit comparison or a 32 bit comparison is done. This selection is made via the associated compare word1 register bit 9. If a 16 bit comparison is selected, then a 16 bit mask is also available to the user to select which bits should be compared. If the 32 bit compare option is selected, then no mask is available. The byte at the OFFSET number of bytes from the index start is compared thru bits 7 to 0 of the configured VALUE. The byte at the OFFSET number of bytes + 1 from the index start is compared thru bits 15 to 8 of the configured VALUE and so on. The OFFSET can be configured to be from 0 to 127 bytes from either the start of the frame, the byte following the therType field (last EtherType in the header if the frame is VLAN tagged), the byte following the IP header (IPv4 or IPv6) or from the byte following the start of the TCP/UDP header. The required number of Type 2 screening registers up to a maximum of 32 is configurable in the gem defines file and have been allocated APB address space between 0x700 and 0x7fc. Note. when using RX Partial Store and Forward mode and priority queues, the frame offset must be less than the Partial Store and Forward watermark. If the offset is higher than the watermark value it's not possible to identify the priority queue before the frame is sent to the AMBA interface, and an incorrect priority queue may be used. '
  [31:16] COMPARE_VALUE_TYPE2 — 2 byte Compare Value. If bit 9 of the associated compare_word1 register is set, then the byte stored in bits [23:16] is compared against the byte in the received frame from the selected offset+2 and the byte stored in bits [31:24] is compared against the byte in the received frame from the selected offset+3. If bit 9 of the associated compare_word1 register is clear, then the byte stored in bits [23:16] is compared against the byte in the received frame from the selected offset+0 and the byte stored in bits [31:24] is compared against the byte in the received frame from the selected offset+1.
  [15:0] MASK_VALUE — These bits can be either a 2 byte mask field or an additional 2 byte Compare Value. If bit 9 of the associated compare_word1 register is set, then the byte stored in bits [7:0] is compared against the byte in the received frame from the selected offset+0 and the byte stored in bits [15:8] is compared against the byte in the received frame from the selected offset+1. If bit 9 of the associated compare_word1 register is clear, these bits become a direct 2-byte mask for the 2-byte compare register in bits [31:16].
0x1704 TYPE2_COMPARE_0_WORD_1 — 'Type2 Compare Word 1'
  [31:10] RSVD_31_10 ro
  [9] DISABLE_MASK — 'This bit is used to control whether the compare register word_0 contains a 4-byte compare value, or a 2-byte compare value with a 2-byte mask value. 1 - 4-byte compare value 0 - 2-byte compare, 2-byte mask '
  [8:7] COMPARE_OFFSET — 'Compare byte offset. 00 : Offset from beginning of the frame. 01 : Offset from byte after Ether Type. 10 : Offset from byte following end of IP header. 11 : Offset from byte following end of TCP/UDP header' If bit 9 of the associated compare_word1 register is set, then the byte stored in bits [23:16] is compared against the byte in the received frame from the selected offset+2 and the byte stored in bits [31:24] is compared against the byte in the received frame from the selected offset+3. If bit 9 of the associated compare_word1 register is clear, then the byte stored in bits [23:16] is compared against the byte in the received frame from the selected offset+0 and the byte stored in bits [31:24] is compared against the byte in the received frame from the selected offset+1.
  [6:0] OFFSET_VALUE — 'Offset value in bytes'
{0x1700+8i} TYPE2_COMPARE_{i}_WORD_0 (i=1..31) — same as type2_compare_0_word_0
  fields as TYPE2_COMPARE_0_WORD_0
{0x1704+8i} TYPE2_COMPARE_{i}_WORD_1 (i=1..31) — same as type2_compare_0_word_1
  fields as TYPE2_COMPARE_0_WORD_1
